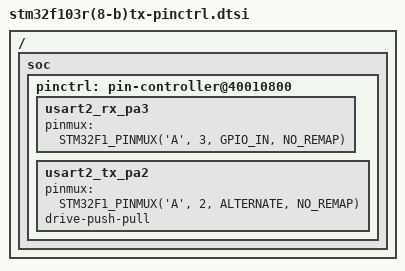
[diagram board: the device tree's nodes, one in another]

/*
 * NOTE: NOT autogenerated file using stm32_pinctrl_gen.py. Do not erase !!
 *
 * SPDX-License-Identifier: Apache-2.0
 */

#include <dt-bindings/pinctrl/stm32f1-pinctrl.h>

/ {
	soc {
		pinctrl: pin-controller@40010800 {
			/* UART_RX */
			usart2_rx_pa3: usart2_rx_pa3 {
				pinmux = <STM32F1_PINMUX('A', 3, GPIO_IN, NO_REMAP)>;
			};

			/* UART_TX */
			usart2_tx_pa2: usart2_tx_pa2 {
				pinmux = <STM32F1_PINMUX('A', 2, ALTERNATE, NO_REMAP)>;
				drive-push-pull;
			};

		};
	};
};
